# SN32F400 register map
Vendor: SONiX Technology Co., Ltd.; Series: SN32F400; File version: 1.1
CPU: CM0 r0p0, little endian, no MPU, no FPU, 2 interrupt priority bits
Registers are 32-bit, read-write, reset 0x0 unless marked. A register's access mark holds for its fields unless they carry their own. Offsets are from the block's base; [hi:lo] are bit positions; 'fields as' and 'values as' point back to an identical list.

## SN_SYS0 — System Control Registers 0
Base 0x40060000
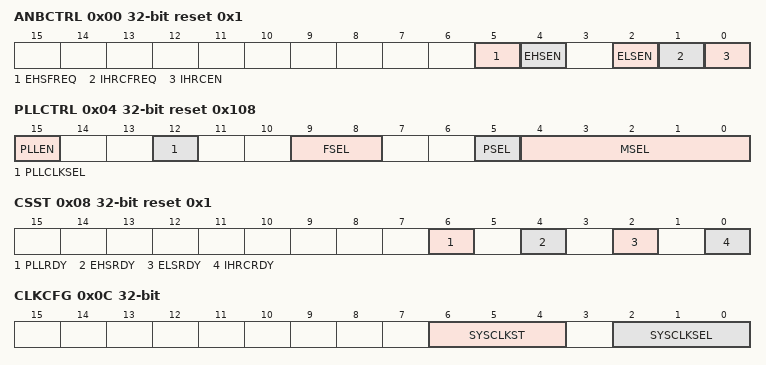
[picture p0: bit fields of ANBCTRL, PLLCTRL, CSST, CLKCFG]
0x00 ANBCTRL reset 0x1 — Offset:0x00 Analog Block Control register
  [5] EHSFREQ — EHS XTAL frequency range
    0=Low (Less equal than 4MHz); 1=High (Greater than 4MHz)
  [4] EHSEN — EHS XTAL enable
    0=Disable EHS Xtal; 1=Enable EHS Xtal
  [2] ELSEN — ELS XTAL enable
    0=Disable ELS Xtal; 1=Enable ELS Xtal
  [1] IHRCFREQ — IHRC frequency
    0=12MHz (IHRC 12MHz); 1=48MHz (IHRC 48MHz)
  [0] IHRCEN — IHRC enable
    0=Disable IHRC; 1=Enable IHRC
0x04 PLLCTRL reset 0x108 — Offset:0x04 PLL Control register
  [15] PLLEN — PLL enable
    0=Disable PLL; 1=Enable PLL
  [12] PLLCLKSEL — PLL clock source
    0=IHRC (12MHz); 1=EHS XTAL (10MHz~25MHz)
  [9:8] FSEL — F value
    1=001b (F=1); 2=010b (F=2); 3=011b (F=3)
  [5] PSEL — P value
    0=P=2; 1=P=4
  [4:0] MSEL — M value
0x08 CSST ro reset 0x1 — Offset:0x08 Clock Source Status register
  [6] PLLRDY — PLL ready flag
    0=Not Locked (PLL is Not locked); 1=Locked (PLL is locked)
  [4] EHSRDY — EHS XTAL ready flag
    0=Not Ready (EHS Xtal is Not Ready); 1=Ready (EHS Xtal is Ready)
  [2] ELSRDY — ELS XTAL ready flag
    0=Not Ready (ELS Xtal is Not Ready); 1=Ready (ELS Xtal is Ready)
  [0] IHRCRDY — IHRC ready flag
    0=Not Ready (IHRC is Not Ready); 1=Ready (IHRC is Ready)
0x0C CLKCFG — Offset:0x0C System Clock Configuration register
  [6:4] SYSCLKST ro — System clock switch status
    0=IHRC (IHRC is used as system clock); 1=ILRC (ILRC is used as system clock); 2=EHS XTAL (EHS XTAL is used as system clock); 3=ELS XTAL (ELS XTAL is used as system clock); 4=PLL (PLL output is used as system clock)
  [2:0] SYSCLKSEL — System clock source selection
    0=IHRC (HCLK=IHRC); 1=ILRC (HCLK=ILRC); 2=EHS XTAL (HCLK=EHS XTAL); 3=ELS XTAL (HCLK=ELS XTAL); 4=PLL Output (HCLK=PLL output)
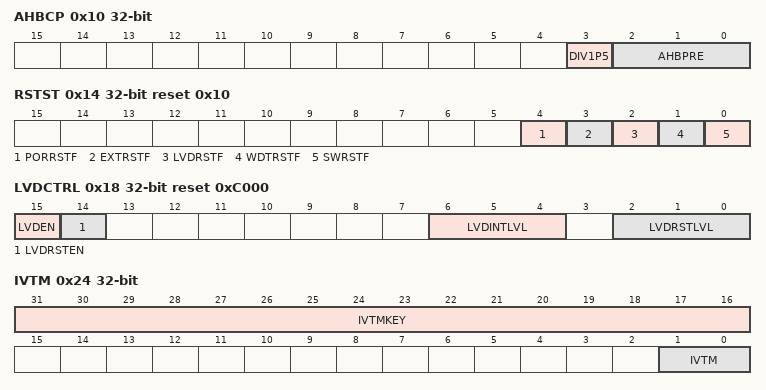
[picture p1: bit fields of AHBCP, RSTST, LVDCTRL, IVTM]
0x10 AHBCP — Offset:0x10 AHB Clock Prescale register
  [3] DIV1P5 — SYSCLK prescaler
    0=DIV1 (SYSCLK = SYSCLK/1); 1=DIV1P5 (SYSCLK = SYSCLK/1.5)
  [2:0] AHBPRE — AHB clock source prescaler
    0=000b (FAHB=FSYSCLK/1); 1=001b (FAHB=FSYSCLK/2); 2=010b (FAHB=FSYSCLK/4); 3=011b (FAHB=FSYSCLK/8); 4=100b (FAHB=FSYSCLK/16); 5=101b (FAHB=FSYSCLK/32); 6=110b (FAHB=FSYSCLK/64); 7=111b (FAHB=FSYSCLK/128)
0x14 RSTST reset 0x10 — Offset:0x14 System Reset Status register
  [4] PORRSTF — POR reset flag
    0=None (No POR occurred); 1=POR (POR occurred)
  [3] EXTRSTF — External reset flag
    0=None (No Extenral reset occurred); 1=External reset occurred
  [2] LVDRSTF — LVD reset flag
    0=None (No LVD reset occurred); 1=LVD reset occurred
  [1] WDTRSTF — WDT reset flag
    0=None (No WDT reset occurred); 1=WDR reset (WDT reset occurred)
  [0] SWRSTF — Software reset flag
    0=None (No SW reset occurred); 1=SW reset occurred
0x18 LVDCTRL reset 0xC000 — Offset:0x18 LVD Control register
  [15] LVDEN — LVD enable
    0=Disable LVD; 1=Enable LVD
  [14] LVDRSTEN — LVD Reset enable
    0=Disable LVD reset; 1=Enable LVD reset
  [6:4] LVDINTLVL — LVD interrupt level
    0=RSV (Reserved for system); 1=2.1V (LVD interrupt threshold is 2.1V); 2=2.5V (LVD interrupt threshold is 2.5V); 3=2.9V (LVD interrupt threshold is 2.9V); 4=3.3V (LVD interrupt threshold is 3.3V); 5=3.7V (LVD interrupt threshold is 3.7V); 6=4.1V (LVD interrupt threshold is 4.1V); 7=4.5V (LVD interrupt threshold is 4.5V)
  [2:0] LVDRSTLVL — LVD reset level
    0=RSV (Reserved for System); 1=2.1V (LVD reset threshold is 2.1V); 2=2.5V (LVD reset threshold is 2.5V); 3=2.9V (LVD reset threshold is 2.9V); 4=3.3V (LVD reset threshold is 3.3V); 5=3.7V (LVD reset threshold is 3.7V); 6=4.1V (LVD reset threshold is 4.1V); 7=4.5V (LVD reset threshold is 4.5V)
0x1C EXRSTCTRL reset 0x1 — Offset:0x1C External Reset Pin Control register
  [0] RESETDIS — External reset pin disable
    0=Enable (P3.7 acts as nRESET pin); 1=Disable (P3.7 acts as GPIO pin)
0x20 SWDCTRL — Offset:0x20 SWD Pin Control register
  [0] SWDDIS — SWD pin disable
    0=Enable SWD pins; 1=Disable SWD pins
0x24 IVTM — Offset:0x24 Interrupt Vector Table Mapping register
  [31:16] IVTMKEY wo — IVTM register key
  [1:0] IVTM — Interrupt table mapping selection
    0=000b (Map to Boot ROM); 1=001b (Map to User ROM); 2=010b (Map to SRAM)
0x30 ANTIEFT — Offset:0x30 Hold Clock Control register
  [3:0] AEFT — HW anti-EFT ability
    0=No (Disable); 1=LV5 (Level 5); 2=LV6 (Level 6); 3=LV7 (Level 7); 4=LV8 (Level 8 (Strongest)); 9=LV1 (Level 1 (Weakest)); 10=LV2 (Level 2); 11=LV3 (Level 3); 12=LV4 (Level 4)
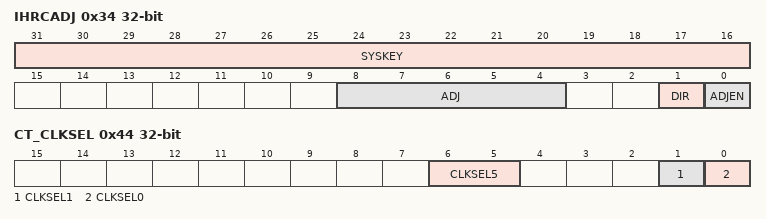
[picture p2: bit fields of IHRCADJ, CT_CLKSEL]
0x34 IHRCADJ — Offset:0x34 IHRC Frequency Adjustment register
  [31:16] SYSKEY wo — System register key
  [8:4] ADJ — IHRC frequency adjusting bits
  [1] DIR — IHRC frequency adjusting direction bit
    0=Positive direction; 1=Negative direction
  [0] ADJEN — IHRC frequency adjustment enable bit
    0=Disable IHRC frequency adjustment; 1=Enable IHRC frequency adjustment
0x44 CT_CLKSEL — Offset:0x44 CT16Bn PCLK Clock Source Select register
  [6:5] CLKSEL5 — CT16B5 PCLK source
    0=HCLK (CT16Bn PCLK source=HCLK); 1=PLL_VCO (CT16Bn PCLK source=PLL_VCO); 2=ELS Xtal (CT16Bn PCLK source=ELS Xtal); 3=ILRC (CT16Bn PCLK source=ILRC)
  [1] CLKSEL1 — CT16B1 PCLK source
    0=HCLK (CT16Bn PCLK source=HCLK); 1=PLL_VCO (CT16Bn PCLK source=PLL_VCO)
  [0] CLKSEL0 — CT16B0 PCLK source
    values as CLKSEL1
